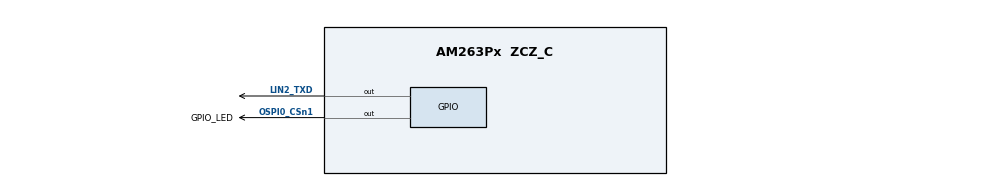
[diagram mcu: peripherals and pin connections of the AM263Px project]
/**
 * @cliArgs --device "AM263Px" --package "ZCZ_C" --part "AM263P1" --context "r5fss0-0" --product "MCU_PLUS_SDK@07.03.01"
 * @versions {"tool":"1.17.0+3128"}
 */

/**
 * Import the modules used in this configuration.
 */
const led        = scripting.addModule("/board/led/led", {}, false);
const led1       = led.addInstance();
const led2       = led.addInstance();
const led3       = led.addInstance();
const gpio       = scripting.addModule("/drivers/gpio/gpio", {}, false);
const gpio1      = gpio.addInstance();
const gpio2      = gpio.addInstance();
const i2c        = scripting.addModule("/drivers/i2c/i2c", {}, false);
const i2c1       = i2c.addInstance();
const clock      = scripting.addModule("/kernel/dpl/clock");
const debug_log  = scripting.addModule("/kernel/dpl/debug_log");
const mpu_armv7  = scripting.addModule("/kernel/dpl/mpu_armv7", {}, false);
const mpu_armv71 = mpu_armv7.addInstance();
const mpu_armv72 = mpu_armv7.addInstance();
const mpu_armv73 = mpu_armv7.addInstance();
const mpu_armv74 = mpu_armv7.addInstance();

/**
 * Write custom configuration values to the imported modules.
 */
led1.$name = "CONFIG_LED_GPIO";

led2.$name = "CONFIG_LED_TPIC";
led2.name  = "TPIC2810";

led3.$name = "CONFIG_LED0";

led1.peripheralDriver      = gpio1;
gpio1.$name                = "GPIO_LED";
gpio1.pinDir               = "OUTPUT";
gpio1.GPIO.gpioPin.$assign = "OSPI0_CSn1";

gpio2.$name                = "CONFIG_GPIO0";
led3.peripheralDriver      = gpio2;
gpio2.GPIO.gpioPin.$assign = "LIN2_TXD";

i2c1.$name            = "CONFIG_I2C0";
led2.peripheralDriver = i2c1;
i2c1.I2C.$assign      = "I2C2";
i2c1.I2C.SCL.$assign  = "UART0_RTSn";
i2c1.I2C.SDA.$assign  = "UART0_CTSn";

debug_log.enableUartLog            = true;
debug_log.uartLog.$name            = "CONFIG_UART0";
debug_log.uartLog.UART.RXD.$assign = "UART0_RXD";
debug_log.uartLog.UART.TXD.$assign = "UART0_TXD";

mpu_armv71.$name             = "CONFIG_MPU_REGION0";
mpu_armv71.size              = 31;
mpu_armv71.attributes        = "Device";
mpu_armv71.accessPermissions = "Supervisor RD+WR, User RD";
mpu_armv71.allowExecute      = false;

mpu_armv72.$name             = "CONFIG_MPU_REGION1";
mpu_armv72.size              = 15;
mpu_armv72.accessPermissions = "Supervisor RD+WR, User RD";

mpu_armv73.$name             = "CONFIG_MPU_REGION2";
mpu_armv73.baseAddr          = 0x41010000;
mpu_armv73.size              = 15;
mpu_armv73.accessPermissions = "Supervisor RD+WR, User RD";

mpu_armv74.$name             = "CONFIG_MPU_REGION3";
mpu_armv74.baseAddr          = 0x70000000;
mpu_armv74.size              = 21;
mpu_armv74.accessPermissions = "Supervisor RD+WR, User RD";

/**
 * Pinmux solution for unlocked pins/peripherals. This ensures that minor changes to the automatic solver in a future
 * version of the tool will not impact the pinmux you originally saw.  These lines can be completely deleted in order to
 * re-solve from scratch.
 */
gpio1.GPIO.$suggestSolution             = "GPIO";
gpio2.GPIO.$suggestSolution             = "GPIO";
debug_log.uartLog.UART.$suggestSolution = "UART0";
